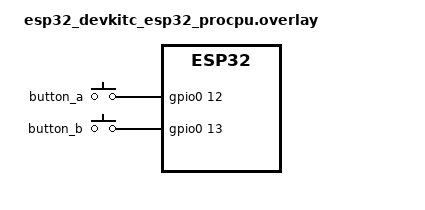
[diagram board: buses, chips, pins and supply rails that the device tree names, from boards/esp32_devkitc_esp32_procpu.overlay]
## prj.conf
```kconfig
CONFIG_ESP32_USE_UNSUPPORTED_REVISION=y
CONFIG_LOG=y
CONFIG_INPUT=y
CONFIG_GPIO=y
```

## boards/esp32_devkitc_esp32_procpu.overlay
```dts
/ {
	buttons {
		compatible = "gpio-keys";
		button_a: button0 {
			gpios = <&gpio0 12 GPIO_ACTIVE_HIGH>;
			zephyr,code = <INPUT_KEY_0>;
		};
		button_b: button1 {
			gpios = <&gpio0 13 GPIO_ACTIVE_HIGH>;
			zephyr,code = <INPUT_KEY_1>;
		};
	};
};
```

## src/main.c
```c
#include "zephyr/dt-bindings/input/input-event-codes.h"
#include <zephyr/device.h>
#include <zephyr/drivers/gpio.h>
#include <zephyr/input/input.h>
#include <zephyr/kernel.h>
#include <zephyr/logging/log.h>

LOG_MODULE_REGISTER(main, LOG_LEVEL_DBG);

static void button_input_cb(struct input_event *evt, void *user_data) {
  if (evt->sync == 0) {
    return;
  }
  if (evt->value) {
    if (evt->code == INPUT_KEY_0) {
      LOG_INF("BUTTON A PRESSED");
    } else if (evt->code == INPUT_KEY_1) {
      LOG_INF("BUTTON B PRESSED");
    }
  }
}

INPUT_CALLBACK_DEFINE(DEVICE_DT_GET(DT_PATH(buttons)), button_input_cb, NULL);

int main() {
  static const struct device *input_dev = DEVICE_DT_GET(DT_PATH(buttons));
  if (!device_is_ready(input_dev)) {
    LOG_ERR_DEVICE_NOT_READY(input_dev);
    return -1;
  }
  return 0;
}
```
